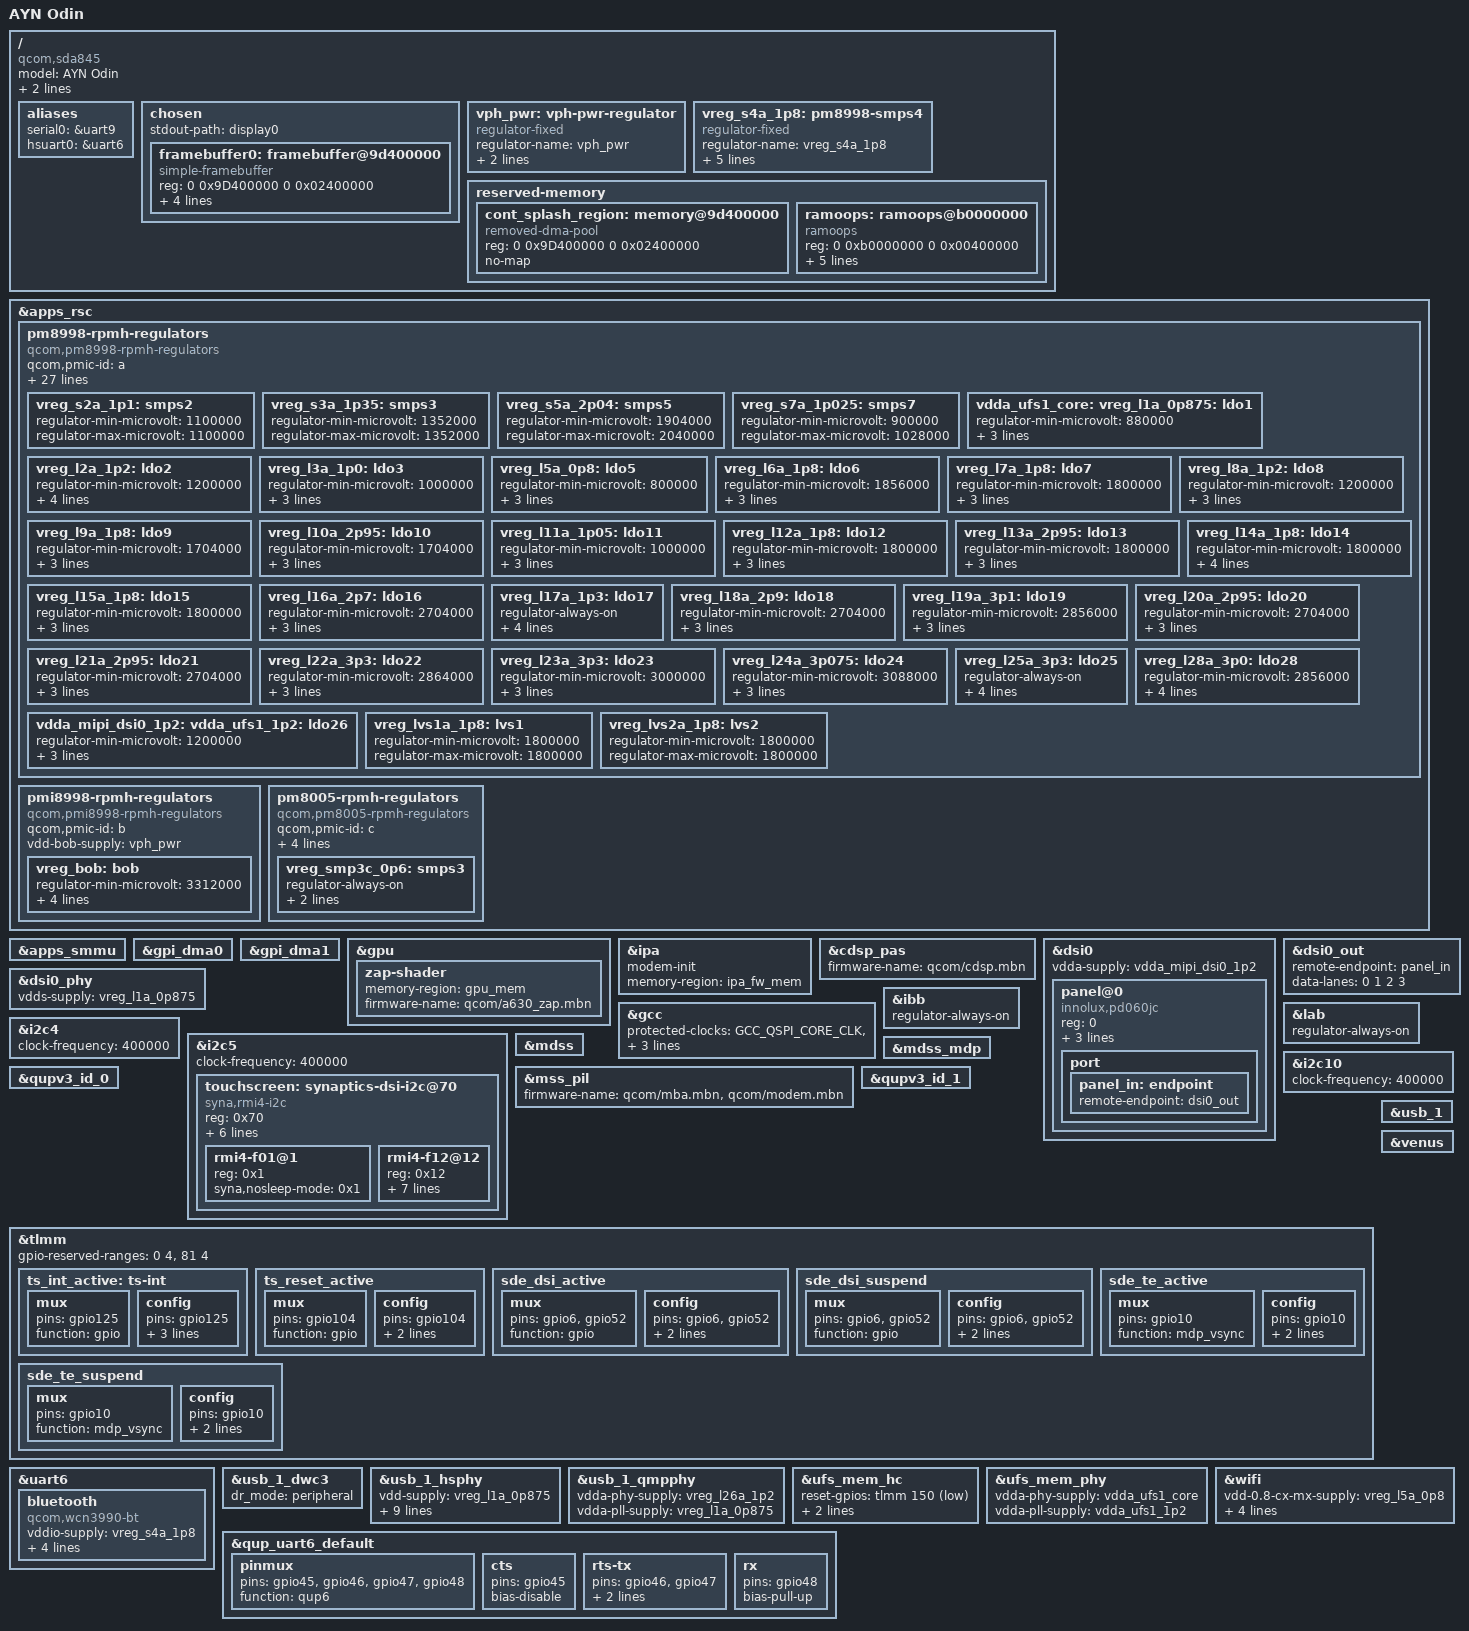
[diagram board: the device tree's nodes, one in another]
// SPDX-License-Identifier: GPL-2.0
/*
 * Copyright (c) 2020, Xilin Wu <strongtz@yeah.net>
 */

/dts-v1/;

#include <dt-bindings/gpio/gpio.h>
#include <dt-bindings/pinctrl/qcom,pmic-gpio.h>
#include <dt-bindings/regulator/qcom,rpmh-regulator.h>
#include <dt-bindings/input/linux-event-codes.h>
#include "sdm845.dtsi"

// Needed for some GPIO (like the volume buttons)
#include "pm8998.dtsi"
#include "pmi8998.dtsi"
#include "pm8005.dtsi"

/ {
	model = "AYN Odin";
	compatible = "qcom,sda845", "qcom,sdm845", "qcom,sdm845-mtp";
	/* required for bootloader to select correct board. 
	 * It might not be needed tho, since we're usually using UEFI boot
	 */
	qcom,board-id = <0x08 0x00>;
	qcom,msm-id = <0x155 0x20001>;

	aliases {
		serial0 = &uart9;
		hsuart0 = &uart6;
	};

	chosen {
		#address-cells = <2>;
		#size-cells = <2>;
		ranges;

		// For simplefb hack
		stdout-path = "display0";

		/* hack: use framebuffer setup by bootloader.
		 * the address is taken from the bootloader config (strings xbl.img | grep "Display Reserved")
		 */
		framebuffer0: framebuffer@9d400000 {
			compatible = "simple-framebuffer";
			reg = <0 0x9D400000 0 0x02400000>;
			width = <1080>;
			height = <1920>;
			stride = <(1080 * 4)>;
			format = "a8r8g8b8";
			status = "okay";
		};
	};

	vph_pwr: vph-pwr-regulator {
		compatible = "regulator-fixed";
		regulator-name = "vph_pwr";
		regulator-min-microvolt = <3700000>;
		regulator-max-microvolt = <3700000>;
	};
	
	/*
	 * Apparently RPMh does not provide support for PM8998 S4 because it
	 * is always-on; model it as a fixed regulator.
	 */
	vreg_s4a_1p8: pm8998-smps4 {
		compatible = "regulator-fixed";
		regulator-name = "vreg_s4a_1p8";
		regulator-min-microvolt = <1800000>;
		regulator-max-microvolt = <1800000>;
		regulator-always-on;
		regulator-boot-on;
		vin-supply = <&vph_pwr>;
	};

	/*
	gpio_keys {
		compatible = "gpio-keys";
		autorepeat;

		pinctrl-names = "default";
		pinctrl-0 = <&vol_up_pin_a>;

		vol-up {
			label = "Volume Up";
			linux,code = <KEY_VOLUMEUP>;
			gpios = <&pm8998_gpio 6 GPIO_ACTIVE_LOW>;
		};
	};
	*/

};


&apps_rsc {
	pm8998-rpmh-regulators {
		compatible = "qcom,pm8998-rpmh-regulators";
		qcom,pmic-id = "a";
		vdd-s1-supply = <&vph_pwr>;
		vdd-s2-supply = <&vph_pwr>;
		vdd-s3-supply = <&vph_pwr>;
		vdd-s4-supply = <&vph_pwr>;
		vdd-s5-supply = <&vph_pwr>;
		vdd-s6-supply = <&vph_pwr>;
		vdd-s7-supply = <&vph_pwr>;
		vdd-s8-supply = <&vph_pwr>;
		vdd-s9-supply = <&vph_pwr>;
		vdd-s10-supply = <&vph_pwr>;
		vdd-s11-supply = <&vph_pwr>;
		vdd-s12-supply = <&vph_pwr>;
		vdd-s13-supply = <&vph_pwr>;
		vdd-l1-l27-supply = <&vreg_s7a_1p025>;
		vdd-l2-l8-l17-supply = <&vreg_s3a_1p35>;
		vdd-l3-l11-supply = <&vreg_s7a_1p025>;
		vdd-l4-l5-supply = <&vreg_s7a_1p025>;
		vdd-l6-supply = <&vph_pwr>;
		vdd-l7-l12-l14-l15-supply = <&vreg_s5a_2p04>;
		vdd-l9-supply = <&vreg_bob>;
		vdd-l10-l23-l25-supply = <&vreg_bob>;
		vdd-l13-l19-l21-supply = <&vreg_bob>;
		vdd-l16-l28-supply = <&vreg_bob>;
		vdd-l18-l22-supply = <&vreg_bob>;
		vdd-l20-l24-supply = <&vreg_bob>;
		vdd-l26-supply = <&vreg_s3a_1p35>;
		vin-lvs-1-2-supply = <&vreg_s4a_1p8>;

		vreg_s2a_1p1: smps2 {
			regulator-min-microvolt = <1100000>;
			regulator-max-microvolt = <1100000>;
		};

		vreg_s3a_1p35: smps3 {
			regulator-min-microvolt = <1352000>;
			regulator-max-microvolt = <1352000>;
		};

		vreg_s5a_2p04: smps5 {
			regulator-min-microvolt = <1904000>;
			regulator-max-microvolt = <2040000>;
		};

		vreg_s7a_1p025: smps7 {
			regulator-min-microvolt = <900000>;
			regulator-max-microvolt = <1028000>;
		};

		vdda_ufs1_core:
		vreg_l1a_0p875: ldo1 {
			regulator-min-microvolt = <880000>;
			regulator-max-microvolt = <880000>;
			regulator-initial-mode = <RPMH_REGULATOR_MODE_HPM>;
		};

		vreg_l2a_1p2: ldo2 {
			regulator-min-microvolt = <1200000>;
			regulator-max-microvolt = <1200000>;
			regulator-initial-mode = <RPMH_REGULATOR_MODE_HPM>;
			regulator-always-on;
		};

		vreg_l3a_1p0: ldo3 {
			regulator-min-microvolt = <1000000>;
			regulator-max-microvolt = <1000000>;
			regulator-initial-mode = <RPMH_REGULATOR_MODE_HPM>;
		};

		vreg_l5a_0p8: ldo5 {
			regulator-min-microvolt = <800000>;
			regulator-max-microvolt = <800000>;
			regulator-initial-mode = <RPMH_REGULATOR_MODE_HPM>;
		};

		vreg_l6a_1p8: ldo6 {
			regulator-min-microvolt = <1856000>;
			regulator-max-microvolt = <1856000>;
			regulator-initial-mode = <RPMH_REGULATOR_MODE_HPM>;
		};

		vreg_l7a_1p8: ldo7 {
			regulator-min-microvolt = <1800000>;
			regulator-max-microvolt = <1800000>;
			regulator-initial-mode = <RPMH_REGULATOR_MODE_HPM>;
		};

		vreg_l8a_1p2: ldo8 {
			regulator-min-microvolt = <1200000>;
			regulator-max-microvolt = <1248000>;
			regulator-initial-mode = <RPMH_REGULATOR_MODE_HPM>;
		};

		vreg_l9a_1p8: ldo9 {
			regulator-min-microvolt = <1704000>;
			regulator-max-microvolt = <2928000>;
			regulator-initial-mode = <RPMH_REGULATOR_MODE_HPM>;
		};

		vreg_l10a_2p95: ldo10 {
			regulator-min-microvolt = <1704000>;
			regulator-max-microvolt = <2928000>;
			regulator-initial-mode = <RPMH_REGULATOR_MODE_HPM>;
		};

		vreg_l11a_1p05: ldo11 {
			regulator-min-microvolt = <1000000>;
			regulator-max-microvolt = <1048000>;
			regulator-initial-mode = <RPMH_REGULATOR_MODE_HPM>;
		};

		vreg_l12a_1p8: ldo12 {
			regulator-min-microvolt = <1800000>;
			regulator-max-microvolt = <1800000>;
			regulator-initial-mode = <RPMH_REGULATOR_MODE_HPM>;
		};

		vreg_l13a_2p95: ldo13 {
			regulator-min-microvolt = <1800000>;
			regulator-max-microvolt = <2960000>;
			regulator-initial-mode = <RPMH_REGULATOR_MODE_HPM>;
		};
		
		vreg_l14a_1p8: ldo14 {
			regulator-min-microvolt = <1800000>;
			regulator-max-microvolt = <1880000>;
			regulator-always-on;
			regulator-initial-mode = <RPMH_REGULATOR_MODE_HPM>;
		};

		vreg_l15a_1p8: ldo15 {
			regulator-min-microvolt = <1800000>;
			regulator-max-microvolt = <1800000>;
			regulator-initial-mode = <RPMH_REGULATOR_MODE_HPM>;
		};

		vreg_l16a_2p7: ldo16 {
			regulator-min-microvolt = <2704000>;
			regulator-max-microvolt = <2704000>;
			regulator-initial-mode = <RPMH_REGULATOR_MODE_HPM>;
		};

		vreg_l17a_1p3: ldo17 {
			regulator-always-on;
			regulator-min-microvolt = <1304000>;
			regulator-max-microvolt = <1304000>;
			regulator-initial-mode = <RPMH_REGULATOR_MODE_HPM>;
		};

		vreg_l18a_2p9: ldo18 {
			regulator-min-microvolt = <2704000>;
			regulator-max-microvolt = <2960000>;
			regulator-initial-mode = <RPMH_REGULATOR_MODE_HPM>;
		};

		vreg_l19a_3p1: ldo19 {
			regulator-min-microvolt = <2856000>;
			regulator-max-microvolt = <3104000>;
			regulator-initial-mode = <RPMH_REGULATOR_MODE_HPM>;
		};

		vreg_l20a_2p95: ldo20 {
			regulator-min-microvolt = <2704000>;
			regulator-max-microvolt = <2960000>;
			regulator-initial-mode = <RPMH_REGULATOR_MODE_HPM>;
		};

		vreg_l21a_2p95: ldo21 {
			regulator-min-microvolt = <2704000>;
			regulator-max-microvolt = <2960000>;
			regulator-initial-mode = <RPMH_REGULATOR_MODE_HPM>;
		};

		vreg_l22a_3p3: ldo22 {
			regulator-min-microvolt = <2864000>;
			regulator-max-microvolt = <3312000>;
			regulator-initial-mode = <RPMH_REGULATOR_MODE_HPM>;
		};

		vreg_l23a_3p3: ldo23 {
			regulator-min-microvolt = <3000000>;
			regulator-max-microvolt = <3312000>;
			regulator-initial-mode = <RPMH_REGULATOR_MODE_HPM>;
		};

		vreg_l24a_3p075: ldo24 {
			regulator-min-microvolt = <3088000>;
			regulator-max-microvolt = <3088000>;
			regulator-initial-mode = <RPMH_REGULATOR_MODE_HPM>;
		};

		vreg_l25a_3p3: ldo25 {
			regulator-always-on;
			regulator-min-microvolt = <3000000>;
			regulator-max-microvolt = <3312000>;
			regulator-initial-mode = <RPMH_REGULATOR_MODE_HPM>;
		};

		vdda_mipi_dsi0_1p2:
		vdda_ufs1_1p2:
		vreg_l26a_1p2: ldo26 {
			regulator-min-microvolt = <1200000>;
			regulator-max-microvolt = <1200000>;
			regulator-initial-mode = <RPMH_REGULATOR_MODE_HPM>;
		};

		vreg_l28a_3p0: ldo28 {
			regulator-min-microvolt = <2856000>;
			regulator-max-microvolt = <3008000>;
			regulator-initial-mode = <RPMH_REGULATOR_MODE_HPM>;
			regulator-always-on;
		};

		vreg_lvs1a_1p8: lvs1 {
			regulator-min-microvolt = <1800000>;
			regulator-max-microvolt = <1800000>;
		};

		vreg_lvs2a_1p8: lvs2 {
			regulator-min-microvolt = <1800000>;
			regulator-max-microvolt = <1800000>;
		};
	};

	pmi8998-rpmh-regulators {
		compatible = "qcom,pmi8998-rpmh-regulators";
		qcom,pmic-id = "b";

		vdd-bob-supply = <&vph_pwr>;

		vreg_bob: bob {
			regulator-min-microvolt = <3312000>;
			regulator-max-microvolt = <3600000>;
			regulator-initial-mode = <RPMH_REGULATOR_MODE_AUTO>;
			regulator-allow-bypass;
		};
	};

	pm8005-rpmh-regulators {
		compatible = "qcom,pm8005-rpmh-regulators";
		qcom,pmic-id = "c";
		
		vdd-s1-supply = <&vph_pwr>;
		vdd-s2-supply = <&vph_pwr>;
		vdd-s3-supply = <&vph_pwr>;
		vdd-s4-supply = <&vph_pwr>;

		vreg_smp3c_0p6: smps3 {
			regulator-always-on;
			regulator-min-microvolt = <600000>;
			regulator-max-microvolt = <600000>;
		};
	};
};

&apps_smmu {
	status = "okay";
};

&gpi_dma0 {
	status = "okay";
};

&gpi_dma1 {
	status = "okay";
};

&gpu {
	zap-shader {
		memory-region = <&gpu_mem>;
		firmware-name = "qcom/a630_zap.mbn";
	};
};

&ipa {
	status = "okay";
	modem-init;
	memory-region = <&ipa_fw_mem>;
};

&cdsp_pas {
	status = "okay";
	firmware-name = "qcom/cdsp.mbn";
};

&dsi0 {
	status = "okay";
	vdda-supply = <&vdda_mipi_dsi0_1p2>;

	#address-cells = <1>;
	#size-cells = <0>;

	panel@0 {
		compatible = "innolux,pd060jc";
		#address-cells = <1>;
		#size-cells = <0>;
		reg = <0>;
		vddi0-supply = <&vreg_l14a_1p8>;
		reset-gpios = <&tlmm 6 GPIO_ACTIVE_LOW>;
		pinctrl-names = "default";
		pinctrl-0 = <&sde_dsi_active &sde_te_active>;
		port {
			panel_in: endpoint {
				remote-endpoint = <&dsi0_out>;
			};
		};
	};
};

&dsi0_out {
	remote-endpoint = <&panel_in>;
	data-lanes = <0 1 2 3>;
};

&dsi0_phy {
	status = "okay";
	vdds-supply = <&vreg_l1a_0p875>;
};

&gcc {
	protected-clocks = <GCC_QSPI_CORE_CLK>,
			   <GCC_QSPI_CORE_CLK_SRC>,
			   <GCC_QSPI_CNOC_PERIPH_AHB_CLK>,
			   <GCC_LPASS_Q6_AXI_CLK>,
			   <GCC_LPASS_SWAY_CLK>;
};

// Keep these always on until we get panel driver working 
&ibb {
	regulator-always-on;
};

&lab {
	regulator-always-on;
};

/* lt8912 */
&i2c4 {
	status = "okay";
	clock-frequency = <400000>;
};

/* synaptics */
&i2c5 {
	status = "okay";
	clock-frequency = <400000>;

	touchscreen: synaptics-dsi-i2c@70 {
		compatible = "syna,rmi4-i2c";
		reg = <0x70>;
		#address-cells = <1>;
		#size-cells = <0>;
		interrupts-extended = <&tlmm 125 0x2008>;
		
		pinctrl-names = "default";
		pinctrl-0 = <&ts_int_active &ts_reset_active>;
		
		vdd-supply = <&vreg_l28a_3p0>;
		vio-supply = <&vreg_l14a_1p8>;
		
		syna,reset-delay-ms = <200>;
		syna,startup-delay-ms = <200>;

		rmi4-f01@1 {
			reg = <0x1>;
			syna,nosleep-mode = <0x1>;
		};

		rmi4-f12@12 {
			reg = <0x12>;
			touchscreen-inverted-x;
			syna,sensor-type = <1>;
			syna,clip-x-low = <0>;
			syna,clip-x-high = <1080>;
			syna,clip-y-low = <0>;
			syna,clip-y-high = <1920>;
			syna,rezero-wait-ms = <200>;
		};
	};

};

/* smb1355 */
&i2c10 {
	status = "okay";
	clock-frequency = <400000>;
};

&mdss {
	status = "okay";
};

&mdss_mdp {
	status = "okay";
};

&mss_pil {
	status = "okay";
	firmware-name = "qcom/mba.mbn", "qcom/modem.mbn";
};

/*
&pm8998_gpio {
	vol_up_pin_a: vol-up-active {
		pins = "gpio6";
		function = "normal";
		input-enable;
		bias-pull-up;
		qcom,drive-strength = <PMIC_GPIO_STRENGTH_NO>;
	};
};

&pm8998_pon {
	resin {
		compatible = "qcom,pm8941-resin";
		interrupts = <0x0 0x8 1 IRQ_TYPE_EDGE_BOTH>;
		debounce = <15625>;
		bias-pull-up;
		linux,code = <KEY_VOLUMEDOWN>;
	};
};*/

&qupv3_id_0 {
	status = "okay";
};

&qupv3_id_1 {
	status = "okay";
};

&tlmm {
	gpio-reserved-ranges = <0 4>, <81 4>;

	ts_int_active: ts-int {
		mux {
			pins = "gpio125";
			function = "gpio";
		};

		config {
			pins = "gpio125";
			drive-strength = <8>;
			bias-pull-up;
			input-enable;
		};
	};

	ts_reset_active: ts_reset_active {
		mux {
			pins = "gpio104";
			function = "gpio";
		};

		config {
			pins = "gpio104";
			bias-pull-up;
			drive-strength = <8>;
		};
	};

	sde_dsi_active: sde_dsi_active {
		mux {
			pins = "gpio6", "gpio52";
			function = "gpio";
		};

		config {
			pins = "gpio6", "gpio52";
			drive-strength = <8>;   /* 8 mA */
			bias-disable = <0>;   /* no pull */
		};
	};

	sde_dsi_suspend: sde_dsi_suspend {
		mux {
			pins = "gpio6", "gpio52";
			function = "gpio";
		};

		config {
			pins = "gpio6", "gpio52";
			drive-strength = <2>;   /* 2 mA */
			bias-pull-down; /* PULL DOWN */
		};
	};

	sde_te_active: sde_te_active {
		mux {
			pins = "gpio10";
			function = "mdp_vsync";
		};

		config {
			pins = "gpio10";
			drive-strength = <2>;   /* 2 mA */
			bias-pull-down; /* PULL DOWN */
		};
	};

	sde_te_suspend: sde_te_suspend {
		mux {
			pins = "gpio10";
			function = "mdp_vsync";
		};

		config {
			pins = "gpio10";
			drive-strength = <2>;   /* 2 mA */
			bias-pull-down; /* PULL DOWN */
		};
	};
};

&uart6 {
	status = "okay";

	bluetooth {
		compatible = "qcom,wcn3990-bt";
		vddio-supply = <&vreg_s4a_1p8>;
		vddxo-supply = <&vreg_l7a_1p8>;
		vddrf-supply = <&vreg_l17a_1p3>;
		vddch0-supply = <&vreg_l25a_3p3>;
		max-speed = <3200000>;
	};
};


&usb_1 {
	status = "okay";
};

&usb_1_dwc3 {
	dr_mode = "peripheral";
};

&usb_1_hsphy {
	status = "okay";

	vdd-supply = <&vreg_l1a_0p875>;
	vdda-pll-supply = <&vreg_l12a_1p8>;
	vdda-phy-dpdm-supply = <&vreg_l24a_3p075>;

	qcom,imp-res-offset-value = <8>;
	qcom,hstx-trim-value = <QUSB2_V2_HSTX_TRIM_21_6_MA>;
	qcom,preemphasis-level = <QUSB2_V2_PREEMPHASIS_5_PERCENT>;
	qcom,preemphasis-width = <QUSB2_V2_PREEMPHASIS_WIDTH_HALF_BIT>;
};

&usb_1_qmpphy {
	status = "okay";

	vdda-phy-supply = <&vreg_l26a_1p2>;
	vdda-pll-supply = <&vreg_l1a_0p875>;
};


&ufs_mem_hc {
	status = "okay";
	reset-gpios = <&tlmm 150 GPIO_ACTIVE_LOW>;
	vcc-supply = <&vreg_l20a_2p95>;
	vcc-max-microamp = <800000>;
};

&ufs_mem_phy {
	status = "okay";
	vdda-phy-supply = <&vdda_ufs1_core>;
	vdda-pll-supply = <&vdda_ufs1_1p2>;
};

&venus {
	status = "okay";
};

&wifi {
	status = "okay";

	vdd-0.8-cx-mx-supply = <&vreg_l5a_0p8>;
	vdd-1.8-xo-supply = <&vreg_l7a_1p8>;
	vdd-1.3-rfa-supply = <&vreg_l17a_1p3>;
	vdd-3.3-ch0-supply = <&vreg_l25a_3p3>;

	qcom,snoc-host-cap-8bit-quirk;
};

/* PINCTRL - additions to nodes defined in sdm845.dtsi */

&qup_uart6_default {
	pinmux {
		 pins = "gpio45", "gpio46", "gpio47", "gpio48";
		 function = "qup6";
	};

	cts {
		pins = "gpio45";
		bias-disable;
	};

	rts-tx {
		pins = "gpio46", "gpio47";
		drive-strength = <2>;
		bias-disable;
	};

	rx {
		pins = "gpio48";
		bias-pull-up;
	};
};

/ {
	reserved-memory {
		/* hack: bootloader framebuffer */
		cont_splash_region: memory@9d400000 {
			compatible = "removed-dma-pool";
			reg = <0 0x9D400000 0 0x02400000>;
			no-map;
		};

		ramoops: ramoops@b0000000 {
			compatible = "ramoops";
			reg = <0 0xb0000000 0 0x00400000>;
			record-size = <0x40000>; /*256x1024*/
			console-size = <0x40000>;
			ftrace-size = <0x40000>;
			pmsg-size = <0x200000>;
			ecc-size = <0x0>;
		};
	};
};
